# ESP32-H4 register map
Vendor: ESPRESSIF SYSTEMS (SHANGHAI) CO., LTD.; Series: ESP32 H-Series; File version: 1
CPU: RV32IMAC r0p0, little endian, no MPU, no FPU, 0 interrupt priority bits
Address unit: 32 bits
Registers are 32-bit, read-write, reset 0x0 unless marked. A register's access mark holds for its fields unless they carry their own. Offsets are from the block's base; [hi:lo] are bit positions.

## ASRC — ASRC Peripheral
Base 0x60028000
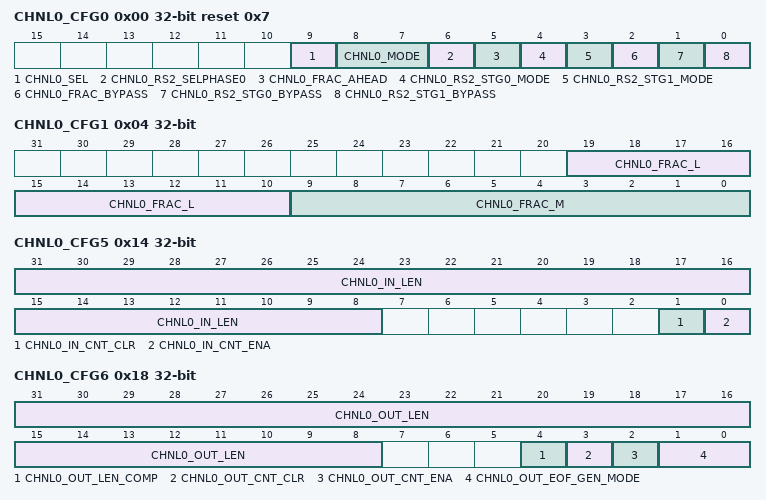
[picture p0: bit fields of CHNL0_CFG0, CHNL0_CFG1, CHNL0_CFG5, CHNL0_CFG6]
0x00 CHNL0_CFG0 reset 0x7 — Control and configuration registers
  [9] CHNL0_SEL — Write the bit to configure which 16bits data will be processing.
  [8:7] CHNL0_MODE — Write the bit to configure the channel mode,0: in and out are both mono, 1: in and out is both dual, 2: in is mono, out is dual, 3, in is dual, out is mono.
  [6] CHNL0_RS2_SELPHASE0 — Set this bit to disable shift phase when 2 interpolation by factor of 2 in channel0.
  [5] CHNL0_FRAC_AHEAD — Set this bit to move fraction re-sampler to the first stage in channel0, it should be 1 when input frequency is higher the output.
  [4] CHNL0_RS2_STG0_MODE — Write this bit to configure stage 0 re-sampler mode in channel0, 0: interpolation by factor of 2, 1: decimation by factor of 2.
  [3] CHNL0_RS2_STG1_MODE — Write this bit to configure stage 1 re-sampler mode in channel0, 0: interpolation by factor of 2, 1: decimation by factor of 2.
  [2] CHNL0_FRAC_BYPASS — Set this bit to bypass fractional re-sampler in channel0.
  [1] CHNL0_RS2_STG0_BYPASS — Set this bit to bypass stage 0 re-sampler in channel0.
  [0] CHNL0_RS2_STG1_BYPASS — Set this bit to bypass stage 1 re-sampler in channel0.
0x04 CHNL0_CFG1 — Control and configuration registers
  [19:10] CHNL0_FRAC_L — Write the bits to specify the nominator of factor of fraction re-sampler in channel0, reg_chnl0_frac_l and reg_chnl0_frac_m are relatively prime.
  [9:0] CHNL0_FRAC_M — Write the bits to specify the denominator of factor of fraction re-sampler in channel0, reg_chnl0_frac_m and reg_chnl0_frac_l are relatively prime.
0x08 CHNL0_CFG2 — Control and configuration registers
  [19:0] CHNL0_FRAC_RECIPL — Write the bits with ((2^19+L)/(2L)) round down in channel0.
0x0C CHNL0_CFG3 wo — Control and configuration registers
  [0] CHNL0_RESET — Set this bit to reset channel0.
0x10 CHNL0_CFG4 — Control and configuration registers
  [0] CHNL0_START — Set this bit to start channel0.
0x14 CHNL0_CFG5 access per field — Control and configuration registers
  [31:8] CHNL0_IN_LEN rw — Write the bits to specify the data byte number of data from the DMA
  [1] CHNL0_IN_CNT_CLR wo — Set this bit to clear in data byte counter.
  [0] CHNL0_IN_CNT_ENA rw — Set this bit to enable in data byte counter.
0x18 CHNL0_CFG6 access per field — Control and configuration registers
  [31:8] CHNL0_OUT_LEN rw — Write the bits to specify the data byte number of data to the DMA, the counter eof will be set when the counter approaches.
  [4] CHNL0_OUT_LEN_COMP rw — Set this bit to enable out data byte counter compensation when using fractional re-sampler and decimation by factor of 2 which results in reg_chnl0_out_cnt >= reg_chnl0_out_len
  [3] CHNL0_OUT_CNT_CLR wo — Set this bit to clear out data byte counter.
  [2] CHNL0_OUT_CNT_ENA rw — Set this bit to enable out data byte counter.
  [1:0] CHNL0_OUT_EOF_GEN_MODE rw — Write the bits to specify the which eof will be written to DMA. 0: counter eof, 1: DMA ineof, 2: both counter eof and DMA ineof, 3 none.
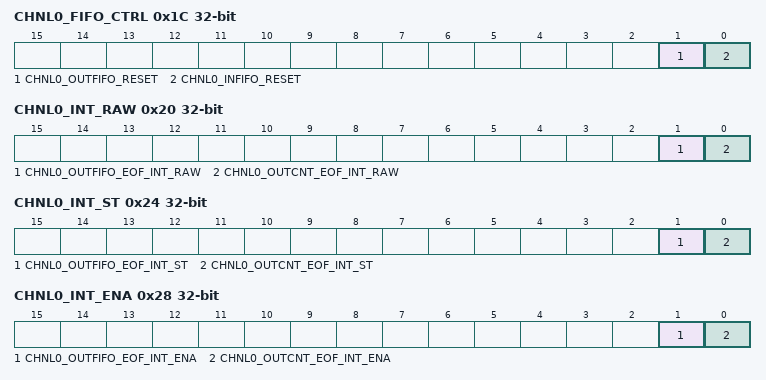
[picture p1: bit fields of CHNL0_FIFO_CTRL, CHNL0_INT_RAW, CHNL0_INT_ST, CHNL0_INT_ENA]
0x1C CHNL0_FIFO_CTRL wo — Control and configuration registers
  [1] CHNL0_OUTFIFO_RESET — Set this bit to reset infifo.
  [0] CHNL0_INFIFO_RESET — Set this bit to reset outfifo.
0x20 CHNL0_INT_RAW — Raw interrupt status
  [1] CHNL0_OUTFIFO_EOF_INT_RAW — This interrupt raw bit turns to high level when getting the eof from DMA and write the several data to DMA.
  [0] CHNL0_OUTCNT_EOF_INT_RAW — This interrupt raw bit turns to high level when the counter approach to reg_out_len.
0x24 CHNL0_INT_ST ro — Masked interrupt status
  [1] CHNL0_OUTFIFO_EOF_INT_ST — This is the status bit for reg_outfifo_eof_int_raw when reg_outfifo_eof_int_ena is set to 1.
  [0] CHNL0_OUTCNT_EOF_INT_ST — This is the status bit for reg_out_cnt_eof_int_raw when reg_out_cnt_eof_int_ena is set to 1.
0x28 CHNL0_INT_ENA — Interrupt enable bits
  [1] CHNL0_OUTFIFO_EOF_INT_ENA — This is the enable bit for reg_outfifo_eof_int_st register.
  [0] CHNL0_OUTCNT_EOF_INT_ENA — This is the enable bit for reg_out_cnt_eof_int_st register.
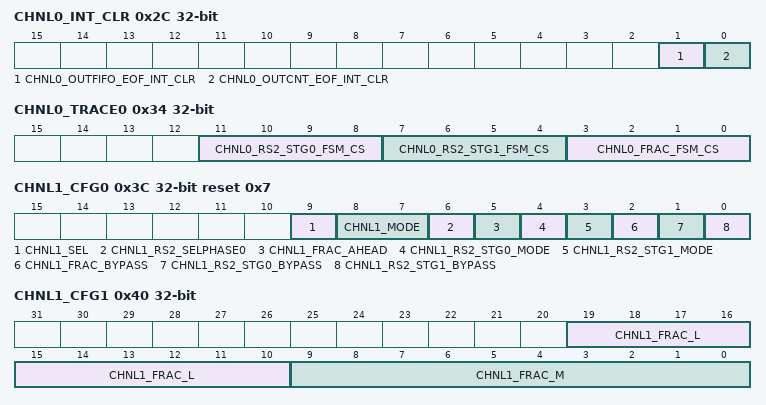
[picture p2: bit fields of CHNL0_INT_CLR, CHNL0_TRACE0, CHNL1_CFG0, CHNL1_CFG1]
0x2C CHNL0_INT_CLR wo — Interrupt clear bits
  [1] CHNL0_OUTFIFO_EOF_INT_CLR — Set this bit to clear the reg_outfifo_eof_int_raw interrupt.
  [0] CHNL0_OUTCNT_EOF_INT_CLR — Set this bit to clear the reg_out_cnt_eof_int_raw interrupt.
0x30 CHNL0_OUT_CNT ro — Status Registers
  [23:0] CHNL0_OUT_CNT — Represents the bytes numbers send to the DMA when EOF occurs.
0x34 CHNL0_TRACE0 ro — Status Registers
  [11:8] CHNL0_RS2_STG0_FSM_CS — Represents re-sampler 2 stag0 status in channel1.
  [7:4] CHNL0_RS2_STG1_FSM_CS — Represents re-sampler 2 stag1 status in channel1.
  [3:0] CHNL0_FRAC_FSM_CS — Represents fractional re-sampler status in channel1.
0x38 CHNL0_TRACE1 ro — Debug Register1
  [23:0] CHNL0_OUT_INC — Represents the samples numbers send to the DMA
0x3C CHNL1_CFG0 reset 0x7 — Control and configuration registers
  [9] CHNL1_SEL — Write the bit to configure which 16bits data will be processing.
  [8:7] CHNL1_MODE — Write the bit to configure the channel mode,0: in and out are both mono, 1: in and out is both dual, 2: in is mono, out is dual, 3, in is dual, out is mono.
  [6] CHNL1_RS2_SELPHASE0 — Set this bit to disable shift phase when 2 interpolation by factor of 2 in channel1.
  [5] CHNL1_FRAC_AHEAD — Set this bit to move fraction re-sampler to the first stage in channel1, it should be 1 when input frequency is higher the output.
  [4] CHNL1_RS2_STG0_MODE — Write this bit to configure stage 0 re-sampler mode in channel1, 0: interpolation by factor of 2, 1: decimation by factor of 2.
  [3] CHNL1_RS2_STG1_MODE — Write this bit to configure stage 1 re-sampler mode in channel1, 0: interpolation by factor of 2, 1: decimation by factor of 2.
  [2] CHNL1_FRAC_BYPASS — Set this bit to bypass fractional re-sampler in channel1.
  [1] CHNL1_RS2_STG0_BYPASS — Set this bit to bypass stage 0 re-sampler in channel1.
  [0] CHNL1_RS2_STG1_BYPASS — Set this bit to bypass stage 1 re-sampler in channel1.
0x40 CHNL1_CFG1 — Control and configuration registers
  [19:10] CHNL1_FRAC_L — Write the bits to specify the nominator of factor of fraction re-sampler in channel1, reg_chnl0_frac_l and reg_chnl0_frac_m are relatively prime.
  [9:0] CHNL1_FRAC_M — Write the bits to specify the denominator of factor of fraction re-sampler in channel1, reg_chnl0_frac_m and reg_chnl0_frac_l are relatively prime.
0x44 CHNL1_CFG2 — Control and configuration registers
  [19:0] CHNL1_FRAC_RECIPL — Write the bits with ((2^19+L)/(2L)) round down in channel1.
0x48 CHNL1_CFG3 wo — Control and configuration registers
  [0] CHNL1_RESET — Set this bit to reset channel1.
0x4C CHNL1_CFG4 — Control and configuration registers
  [0] CHNL1_START — Set this bit to start channel1.
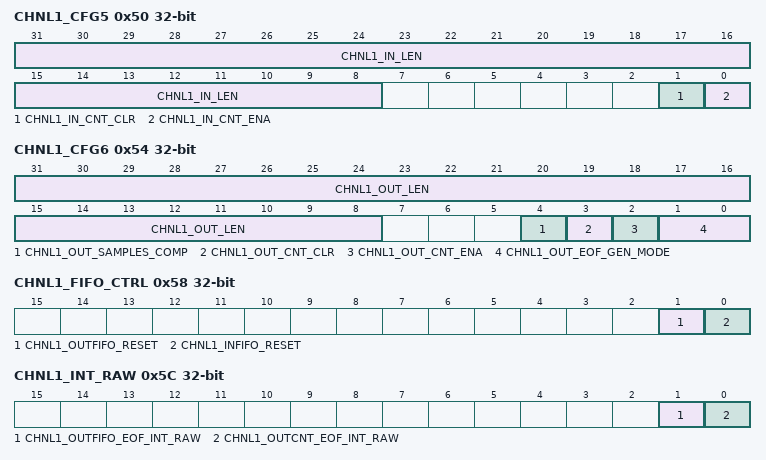
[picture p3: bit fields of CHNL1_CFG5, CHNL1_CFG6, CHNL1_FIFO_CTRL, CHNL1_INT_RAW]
0x50 CHNL1_CFG5 access per field — Control and configuration registers
  [31:8] CHNL1_IN_LEN rw — Write the bits to specify the data byte numbers of data from the DMA
  [1] CHNL1_IN_CNT_CLR wo — Set this bit to clear in data byte counter.
  [0] CHNL1_IN_CNT_ENA rw — Set this bit to enable in data byte counter.
0x54 CHNL1_CFG6 access per field — Control and configuration registers
  [31:8] CHNL1_OUT_LEN rw — Write the bits to specify the data byte number of data to the DMA, the counter eof will be set when the counter approaches.
  [4] CHNL1_OUT_SAMPLES_COMP rw — Set this bit to enable out data byte counter compensation when using fractional re-sampler and decimation by factor of 2 which results in reg_chnl1_out_cnt >= reg_chnl1_out_len
  [3] CHNL1_OUT_CNT_CLR wo — Set this bit to clear out data byte counter.
  [2] CHNL1_OUT_CNT_ENA rw — Set this bit to enable out data byte counter.
  [1:0] CHNL1_OUT_EOF_GEN_MODE rw — Write the bits to specify the which eof will be written to DMA. 0: counter eof, 1: DMA ineof, 2: both counter eof and DMA ineof, 3 none.
0x58 CHNL1_FIFO_CTRL wo — Control and configuration registers
  [1] CHNL1_OUTFIFO_RESET — Set this bit to reset infifo.
  [0] CHNL1_INFIFO_RESET — Set this bit to reset outfifo.
0x5C CHNL1_INT_RAW — Raw interrupt status
  [1] CHNL1_OUTFIFO_EOF_INT_RAW — This interrupt raw bit turns to high level when getting the eof from DMA and write the several data to DMA.
  [0] CHNL1_OUTCNT_EOF_INT_RAW — This interrupt raw bit turns to high level when the counter approach to reg_out_len.
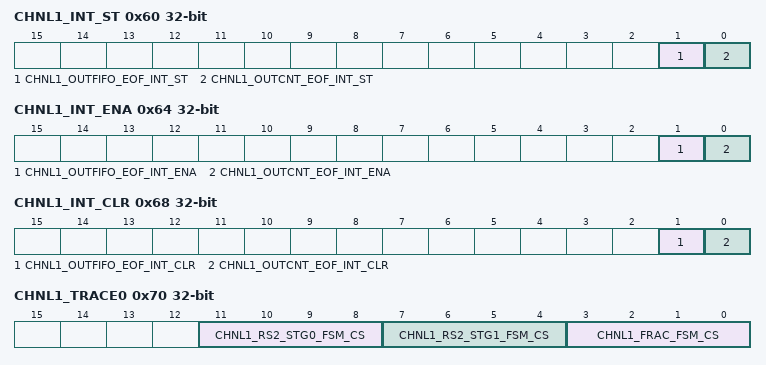
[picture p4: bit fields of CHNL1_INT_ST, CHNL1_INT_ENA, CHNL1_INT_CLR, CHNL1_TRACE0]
0x60 CHNL1_INT_ST ro — Masked interrupt status
  [1] CHNL1_OUTFIFO_EOF_INT_ST — This is the status bit for reg_outfifo_eof_int_raw when reg_outfifo_eof_int_ena is set to 1.
  [0] CHNL1_OUTCNT_EOF_INT_ST — This is the status bit for reg_out_cnt_eof_int_raw when reg_out_cnt_eof_int_ena is set to 1.
0x64 CHNL1_INT_ENA — Interrupt enable bits
  [1] CHNL1_OUTFIFO_EOF_INT_ENA — This is the enable bit for reg_outfifo_eof_int_st register.
  [0] CHNL1_OUTCNT_EOF_INT_ENA — This is the enable bit for reg_out_cnt_eof_int_st register.
0x68 CHNL1_INT_CLR wo — Interrupt clear bits
  [1] CHNL1_OUTFIFO_EOF_INT_CLR — Set this bit to clear the reg_outfifo_eof_int_raw interrupt.
  [0] CHNL1_OUTCNT_EOF_INT_CLR — Set this bit to clear the reg_out_cnt_eof_int_raw interrupt.
0x6C CHNL1_OUT_CNT ro — Status Registers
  [23:0] CHNL1_OUT_CNT — Represents the data byte numbers send to the DMA when EOF occurs.
0x70 CHNL1_TRACE0 ro — Status Registers
  [11:8] CHNL1_RS2_STG0_FSM_CS — Represents re-sampler 2 stag0 status in channel1.
  [7:4] CHNL1_RS2_STG1_FSM_CS — Represents re-sampler 2 stag1 status in channel1.
  [3:0] CHNL1_FRAC_FSM_CS — Represents fractional re-sampler status in channel1.
0x74 CHNL1_TRACE1 ro — Debug Register1
  [23:0] CHNL1_OUT_INC — Represents the data byte numbers send to the DMA
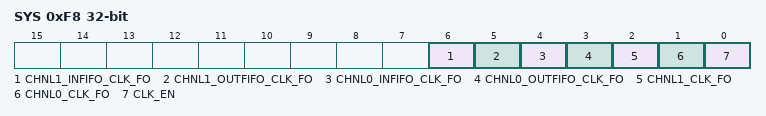
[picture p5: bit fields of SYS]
0xF8 SYS — Control and configuration
  [6] CHNL1_INFIFO_CLK_FO — Set this bit to make channel1 infifo clock free run.
  [5] CHNL1_OUTFIFO_CLK_FO — Set this bit to make channel1 outfifo clock free run.
  [4] CHNL0_INFIFO_CLK_FO — Set this bit to make channel0 infifo clock free run.
  [3] CHNL0_OUTFIFO_CLK_FO — Set this bit to make channel0 outfifo clock free run.
  [2] CHNL1_CLK_FO — Set this bit to make channel1 clock free run.
  [1] CHNL0_CLK_FO — Set this bit to make channel0 clock free run.
  [0] CLK_EN — Reserved
0xFC DATE reset 0x2407240 — Control and configuration registers
  [27:0] DATE — Reserved
